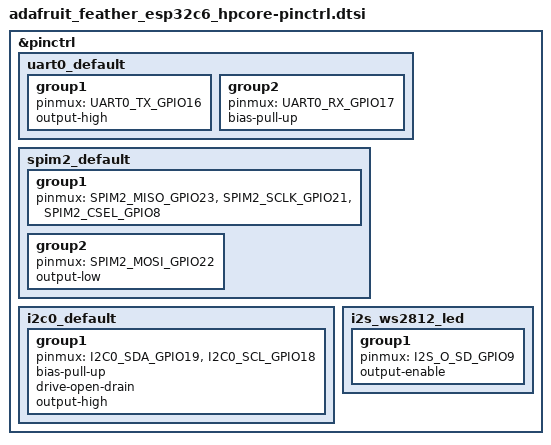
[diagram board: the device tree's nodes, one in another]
/*
 * Copyright (c) 2026 Hong Nguyen <hong.nguyen.k54@gmail.com>
 *
 * SPDX-License-Identifier: Apache-2.0
 */

#include <zephyr/dt-bindings/pinctrl/esp32c6-pinctrl.h>

&pinctrl {
	uart0_default: uart0_default {
		group1 {
			pinmux = <UART0_TX_GPIO16>;
			output-high;
		};

		group2 {
			pinmux = <UART0_RX_GPIO17>;
			bias-pull-up;
		};
	};

	spim2_default: spim2_default {
		group1 {
			pinmux = <SPIM2_MISO_GPIO23>,
				 <SPIM2_SCLK_GPIO21>,
				 <SPIM2_CSEL_GPIO8>;
		};

		group2 {
			pinmux = <SPIM2_MOSI_GPIO22>;
			output-low;
		};
	};

	i2c0_default: i2c0_default {
		group1 {
			pinmux = <I2C0_SDA_GPIO19>,
				 <I2C0_SCL_GPIO18>;
			bias-pull-up;
			drive-open-drain;
			output-high;
		};
	};

	i2s_ws2812_led: i2s_ws2812_led {
		group1 {
			pinmux = <I2S_O_SD_GPIO9>;
			output-enable;
		};
	};
};
